# STM32G554 register map
File version: 2.0.0
CPU: CM33 r0p4, little endian, MPU, FPU, 4 interrupt priority bits
Registers are 32-bit, read-write, reset 0x0 unless marked. A register's access mark holds for its fields unless they carry their own. Offsets are from the block's base; [hi:lo] are bit positions; {n}, {i} and the like mark numbered series; 'fields as' and 'values as' point back to an identical list.

## TIM9 — TIM9 address block description
Base 0x40001800
Same registers: TIM9_S 0x50001800
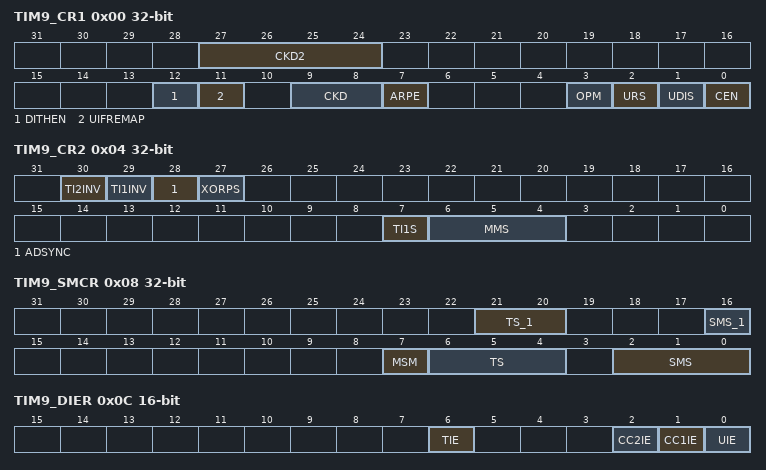
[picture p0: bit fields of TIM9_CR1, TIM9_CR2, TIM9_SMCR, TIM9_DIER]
0x00 TIM9_CR1 — TIM9 control register 1
  [27:24] CKD2 — Clock division 2
    0=No Division; 1=tless thansub>DTS2less than/sub> = 4xtless thansub>DTSless than/sub>; 2=tless thansub>DTS2less than/sub> = 16xtless thansub>DTSless than/sub>; 3=tless thansub>DTS2less than/sub> = 64xtless thansub>DTSless than/sub>; 4=tless thansub>DTS2less than/sub> = 256xtless thansub>DTSless than/sub>; 5=tless thansub>DTS2less than/sub> = 1024xtless thansub>DTSless than/sub>; 6=tless thansub>DTS2less than/sub> = 4096xtless thansub>DTSless than/sub>; 7=tless thansub>DTS2less than/sub> = 16384xtless thansub>DTSless than/sub>; 8=tless thansub>DTS2less than/sub> = 65536xtless thansub>DTSless than/sub>; 9=tless thansub>DTS2less than/sub> = 262144xtless thansub>DTSless than/sub>
  [12] DITHEN — Dithering enable
    0=Dithering disabled; 1=Dithering enabled
  [11] UIFREMAP — UIF status bit remapping
    0=No remapping. UIF status bit is not copied to TIMx_CNT register bit 31.; 1=Remapping enabled. UIF status bit is copied to TIMx_CNT register bit 31.
  [9:8] CKD — Clock division
    0=tless thansub>DTSless than/sub> = tless thansub>tim_ker_ckless than/sub>; 1=tless thansub>DTSless than/sub> = 2 x tless thansub>tim_ker_ckless than/sub>; 2=tless thansub>DTSless than/sub> = 4 x tless thansub>tim_ker_ckless than/sub>; 3=tless thansub>DTSless than/sub> = 8 x tless thansub>tim_ker_ckless than/sub>
  [7] ARPE — Auto-reload preload enable
    0=TIMx_ARR register is not buffered; 1=TIMx_ARR register is buffered
  [3] OPM — One-pulse mode
    0=Counter is not stopped on the update event; 1=Counter stops counting on the next update event (clearing the CEN bit)
  [2] URS — Update request source
    0=Any of the following events generates an update interrupt if enabled. These events can be:; 1=Only counter overflow generates an update interrupt if enabled
  [1] UDIS — Update disable
    0=UEV enabled. An UEV is generated by one of the following events:; 1=UEV disabled. No UEV is generated, shadow registers keep their value (ARR, PSC, CCRx). The counter and the prescaler are reinitialized if the UG bit is set.
  [0] CEN — Counter enable
    0=Counter disabled; 1=Counter enabled
0x04 TIM9_CR2 — TIM12 control register 2
  [30] TI2INV — tim_ti2 signal inversion on XOR gate input
    0=tim_ti2 non-inverted; 1=tim_ti2 inverted
  [29] TI1INV — tim_ti1 signal inversion on XOR gate input
    0=tim_ti1 non-inverted; 1=tim_ti1 inverted
  [28] ADSYNC — ADC synchronization
    0=The timer operates independently from the ADC; 1=The timer operation is synchronized with the ADC clock to provide jitter-free sampling point. This mode can be enabled only with specific ADC / timer clock relationship. Refer to Section216.4.24 for requirements.
  [27] XORPS — XOR gate position selection
    0=XOR gate placed before TI1 filter; 1=XOR gate placed after TI1 and TI2 filters
  [7] TI1S — tim_ti1 selection
    0=The tim_ti1_in[15:0] multiplexer output is connected to tim_ti1 input; 1=The tim_ti1_in[15:0] and tim_ti2_in[15:0] multiplexers output are connected to the tim_ti1 input (XOR combination)
  [6:4] MMS — Master mode selection
    0=Reset - the UG bit from the TIMx_EGR register is used as trigger output (tim_trgo). If the reset is generated by the trigger input (slave mode controller configured in reset mode) then the signal on tim_trgo is delayed compared to the actual reset.; 1=Enable - the Counter Enable signal CNT_EN is used as trigger output (tim_trgo). It is useful to start several timers at the same time or to control a window in which a slave timer is enable. The Counter Enable signal is generated by a logic AND between CEN control bit and the trigger input when configured in gated mode. When the Counter Enable signal is controlled by the trigger input, there is a delay on tim_trgo, except if the master/slave mode is selected (see the MSM bit description in TIMx_SMCR register).; 2=Update - The update event is selected as trigger output (tim_trgo). For instance a master timer can then be used as a prescaler for a slave timer.; 3=Compare Pulse - The trigger output send a positive pulse when the CC1IF flag is to be set (even if it was already high), as soon as a capture or a compare match occurred (tim_trgo); 4=Compare - tim_oc1refc signal is used as trigger output (tim_trgo); 5=Compare - tim_oc2refc signal is used as trigger output (tim_trgo)
0x08 TIM9_SMCR — TIM9 slave mode control register
  [21:20] TS_1 — TS[4:3]
  [16] SMS_1 — SMS[3]
  [7] MSM — Master/Slave mode
    0=No action; 1=The effect of an event on the trigger input (tim_trgi) is delayed to allow a perfect synchronization between the current timer and its slaves (through tim_trgo). It is useful in order to synchronize several timers on a single external event.
  [6:4] TS — TS[2:0]: Trigger selection
    {v}=Internal trigger {v} (tim_itr{v}) (v=0..3); 4=tim_ti1 Edge Detector (tim_ti1f_ed); 5=Filtered Timer Input 1 (tim_ti1fp1); 6=Filtered Timer Input 2 (tim_ti2fp2)
  [2:0] SMS — SMS[2:0]: Slave mode selection
    0=Slave mode disabled - if CEN = 1 then the prescaler is clocked directly by the internal clock; 4=Reset mode - Rising edge of the selected trigger input (tim_trgi) reinitializes the counter and generates an update of the registers; 5=Gated mode - The counter clock is enabled when the trigger input (tim_trgi) is high. The counter stops (but is not reset) as soon as the trigger becomes low. Both start and stop of the counter are controlled.; 6=Trigger mode - The counter starts at a rising edge of the trigger tim_trgi (but it is not reset). Only the start of the counter is controlled.; 7=External clock mode 1 - Rising edges of the selected trigger (tim_trgi) clock the counter
0x0C TIM9_DIER 16-bit — TIM9 interrupt enable register
  [6] TIE — Trigger interrupt enable
    0=Trigger interrupt disabled; 1=Trigger interrupt enabled
  [2] CC2IE — Capture/Compare 2 interrupt enable
    0=CC2 interrupt disabled; 1=CC2 interrupt enabled
  [1] CC1IE — Capture/Compare 1 interrupt enable
    0=CC1 interrupt disabled; 1=CC1 interrupt enabled
  [0] UIE — Update interrupt enable
    0=Update interrupt disabled; 1=Update interrupt enabled
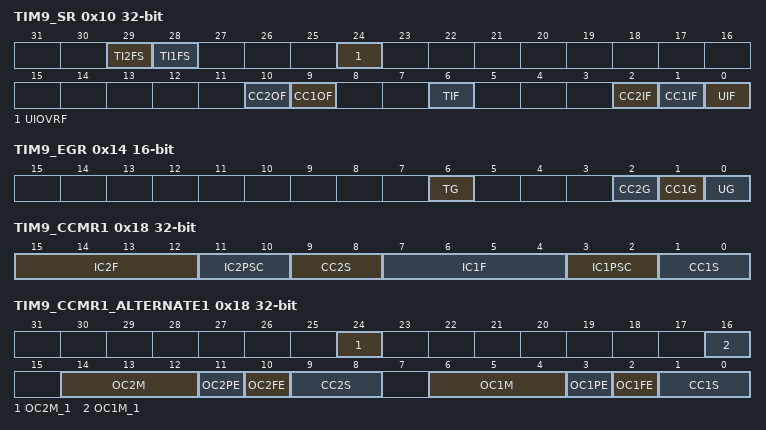
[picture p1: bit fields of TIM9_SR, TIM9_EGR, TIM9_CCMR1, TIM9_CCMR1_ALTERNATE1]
0x10 TIM9_SR — TIM9 status register
  [29] TI2FS ro — tim_ti2f status
    0=tim_ti2f signal is low; 1=tim_ti2f signal is high
  [28] TI1FS ro — tim_ti1f status
    0=tim_ti1f signal is low; 1=tim_ti1f signal is high
  [24] UIOVRF — Update interrupt overrun flag
    0=No update interrupt overrun; 1=Update interrupt overrun
  [10] CC2OF — Capture/compare 2 overcapture flag
  [9] CC1OF — Capture/compare 1 overcapture flag
    0=No overcapture has been detected; 1=The counter value has been captured in TIMx_CCR1 register while CC1IF flag was already set
  [6] TIF — Trigger interrupt flag
    0=No trigger event occurred; 1=Trigger interrupt pending
  [2] CC2IF — Capture/Compare 2 interrupt flag
  [1] CC1IF — Capture/compare 1 interrupt flag
    0=No compare match / No input capture occurred; 1=A compare match or an input capture occurred
  [0] UIF — Update interrupt flag
    0=No update occurred; 1=Update interrupt pending. This bit is set by hardware when the registers are updated:
0x14 TIM9_EGR 16-bit wo — TIM9 event generation register
  [6] TG — Trigger generation
    0=No action; 1=The TIF flag is set in the TIMx_SR register. Related interrupt can occur if enabled
  [2] CC2G — Capture/compare 2 generation
  [1] CC1G — Capture/compare 1 generation
    0=No action; 1=A capture/compare event is generated on channel 1:
  [0] UG — Update generation
    0=No action; 1=Re-initializes the counter and generates an update of the registers. The prescaler counter is also cleared and the prescaler ratio is not affected. The counter is cleared.
0x18 TIM9_CCMR1 — TIM9 capture/compare mode register 1
  [15:12] IC2F — Input capture 2 filter
  [11:10] IC2PSC — Input capture 2 prescaler
  [9:8] CC2S — Capture/compare 2 selection
    0=CC2 channel is configured as output; 1=CC2 channel is configured as input, IC2 is mapped on tim_ti2; 2=CC2 channel is configured as input, IC2 is mapped on tim_ti1; 3=CC2 channel is configured as input, IC2 is mapped on tim_trc. This mode works only if an internal trigger input is selected through the TS bit (TIMx_SMCR register)
  [7:4] IC1F — Input capture 1 filter
    0=No filter, sampling is done at fless thansub>DTSless than/sub>; 1=fless thansub>SAMPLINGless than/sub> = fless thansub>tim_ker_ckless than/sub>, N = 2; 2=fless thansub>SAMPLINGless than/sub> = fless thansub>tim_ker_ckless than/sub>, N = 4; 3=fless thansub>SAMPLINGless than/sub> = fless thansub>tim_ker_ckless than/sub>, N = 8; 4=fless thansub>SAMPLINGless than/sub> = fless thansub>DTSless than/sub>/2, N = 6; 5=fless thansub>SAMPLINGless than/sub> = fless thansub>DTSless than/sub>/2, N = 8; 6=fless thansub>SAMPLINGless than/sub> = fless thansub>DTSless than/sub>/4, N = 6; 7=fless thansub>SAMPLINGless than/sub> = fless thansub>DTSless than/sub>/4, N = 8; 8=fless thansub>SAMPLINGless than/sub> = fless thansub>DTSless than/sub>/8, N = 6; 9=fless thansub>SAMPLINGless than/sub> = fless thansub>DTSless than/sub>/8, N = 8; 10=fless thansub>SAMPLINGless than/sub> = fless thansub>DTSless than/sub>/16, N = 5; 11=fless thansub>SAMPLINGless than/sub> = fless thansub>DTSless than/sub>/16, N = 6; 12=fless thansub>SAMPLINGless than/sub> = fless thansub>DTSless than/sub>/16, N = 8; 13=fless thansub>SAMPLINGless than/sub> = fless thansub>DTSless than/sub>/32, N = 5; 14=fless thansub>SAMPLINGless than/sub> = fless thansub>DTSless than/sub>/32, N = 6; 15=fless thansub>SAMPLINGless than/sub> = fless thansub>DTSless than/sub>/32, N = 8
  [3:2] IC1PSC — Input capture 1 prescaler
    0=no prescaler, capture is done each time an edge is detected on the capture input; 1=capture is done once every 2 events; 2=capture is done once every 4 events; 3=capture is done once every 8 events
  [1:0] CC1S — Capture/Compare 1 selection
    0=CC1 channel is configured as output; 1=CC1 channel is configured as input, tim_ic1 is mapped on tim_ti1; 2=CC1 channel is configured as input, tim_ic1 is mapped on tim_ti2; 3=CC1 channel is configured as input, tim_ic1 is mapped on tim_trc. This mode is working only if an internal trigger input is selected through TS bit (TIMx_SMCR register)
0x18 TIM9_CCMR1_ALTERNATE1 (alternate view of TIM9_CCMR1) — TIM9 capture/compare mode register 1
  [24] OC2M_1 — OC2M[3]
  [16] OC1M_1 — OC1M[3]
  [14:12] OC2M — OC2M[2:0]: Output compare 2 mode
  [11] OC2PE — Output compare 2 preload enable
  [10] OC2FE — Output compare 2 fast enable
  [9:8] CC2S — Capture/Compare 2 selection
    0=CC2 channel is configured as output; 1=CC2 channel is configured as input, IC2 is mapped on tim_ti2; 2=CC2 channel is configured as input, IC2 is mapped on tim_ti1; 3=CC2 channel is configured as input, IC2 is mapped on tim_trc. This mode works only if an internal trigger input is selected through the TS bit (TIMx_SMCR register
  [6:4] OC1M — OC1M[2:0]: Output compare 1 mode (refer to bit 16 for OC1M[3])
    0=Frozen - The comparison between the output compare register TIMx_CCR1 and the counter TIMx_CNT has no effect on the outputs. This mode can be used when the timer serves as a software timebase. When the frozen mode is enabled during timer operation, the ouput keeps the state (active or inactive) it had before entering the frozen state.; 1=Set channel 1 to active level on match. The tim_oc1ref signal is forced high when the TIMx_CNT counter matches the capture/compare register 1 (TIMx_CCR1).; 2=Set channel 1 to inactive level on match. The tim_oc1ref signal is forced low when the TIMx_CNT counter matches the capture/compare register 1 (TIMx_CCR1).; 3=Toggle - tim_oc1ref toggles when TIMx_CNT = TIMx_CCR1; 4=Force inactive level - tim_oc1ref is forced low; 5=Force active level - tim_oc1ref is forced high; 6=PWM mode 1 - channel 1 is active as long as TIMx_CNTless thanTIMx_CCR1 else it is inactive; 7=PWM mode 2 - channel 1 is inactive as long as TIMx_CNTless thanTIMx_CCR1 else it is active
  [3] OC1PE — Output compare 1 preload enable
    0=Preload register on TIMx_CCR1 disabled. TIMx_CCR1 can be written at anytime, the new value is taken into account immediately; 1=Preload register on TIMx_CCR1 enabled. Read/Write operations access the preload register. TIMx_CCR1 preload value is loaded into the active register at each update event
  [2] OC1FE — Output compare 1 fast enable
    0=CC1 behaves normally depending on the counter and CCR1 values even when the trigger is ON. The minimum delay to activate the CC1 output when an edge occurs on the trigger input is 5 clock cycles; 1=An active edge on the trigger input acts like a compare match on the CC1 output. Then, OC is set to the compare level independently of the result of the comparison. Delay to sample the trigger input and to activate CC1 output is reduced to 3 clock cycles. OC1FE acts only if the channel is configured in PWM1 or PWM2 mode.
  [1:0] CC1S — Capture/Compare 1 selection
    0=CC1 channel is configured as output; 1=CC1 channel is configured as input, tim_ic1 is mapped on tim_ti1; 2=CC1 channel is configured as input, tim_ic1 is mapped on tim_ti2; 3=CC1 channel is configured as input, tim_ic1 is mapped on tim_trc. This mode works only if an internal trigger input is selected through the TS bit (TIMx_SMCR register)
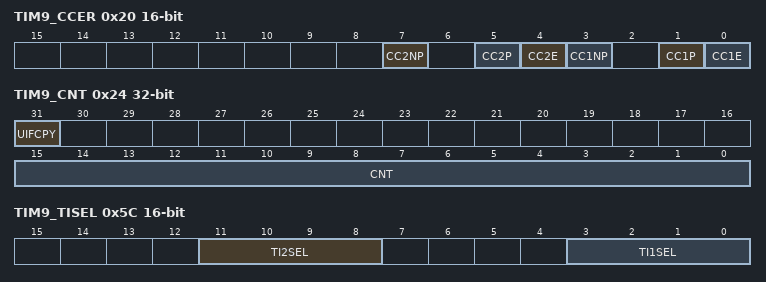
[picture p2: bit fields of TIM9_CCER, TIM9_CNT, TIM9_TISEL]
0x20 TIM9_CCER 16-bit — TIM9 capture/compare enable register
  [7] CC2NP — Capture/Compare 2 output Polarity
  [5] CC2P — Capture/Compare 2 output Polarity
  [4] CC2E — Capture/Compare 2 output enable
  [3] CC1NP — Capture/Compare 1 complementary output Polarity
  [1] CC1P — Capture/Compare 1 output Polarity.
    0=tim_oc1 active high (output mode) / Edge sensitivity selection (input mode, see below); 1=tim_oc1 active low (output mode) / Edge sensitivity selection (input mode, see below)
  [0] CC1E — Capture/Compare 1 output enable.
    0=Capture mode disabled / tim_oc1 is not active; 1=Capture mode enabled / tim_oc1 signal is output on the corresponding output pin
0x24 TIM9_CNT — TIM9 counter
  [31] UIFCPY — UIF Copy
  [15:0] CNT — Counter value
0x28 TIM9_PSC 16-bit — TIM9 prescaler
  [15:0] PSC — Prescaler value
0x2C TIM9_ARR reset 0xFFFF — TIM9 autoreload register
  [19:0] ARR — Auto-reload value
0x34 TIM9_CCR1 — TIM9 capture/compare register 1
  [19:0] CCR1 — Capture/compare 1 value
0x38 TIM9_CCR2 — TIM9 capture/compare register 2
  [19:0] CCR2 — Capture/compare 2 value
0x5C TIM9_TISEL 16-bit — TIM9 timer input selection register
  [11:8] TI2SEL — selects tim_ti2_in[15:0] input
    0=TIMx_CH2 input (tim_ti2_in0); 1=tim_ti2_in1; 4=tim_ti2_in15
  [3:0] TI1SEL — selects tim_ti1_in[15:0] input
    0=TIMx_CH1 input (tim_ti1_in0); 1=tim_ti1_in1; 15=tim_ti1_in15

## TIM12 — TIM12 address block description
Base 0x40002400
Same registers: TIM12_S 0x50002400
Registers as TIM9 (with TIM9 read as TIM12); these are added or differ:
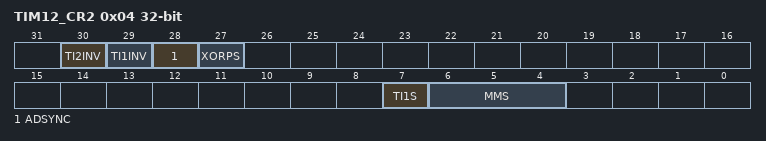
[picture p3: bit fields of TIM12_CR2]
0x04 TIM12_CR2 — TIM12 control register 2
  fields as TIM9.TIM9_CR2
